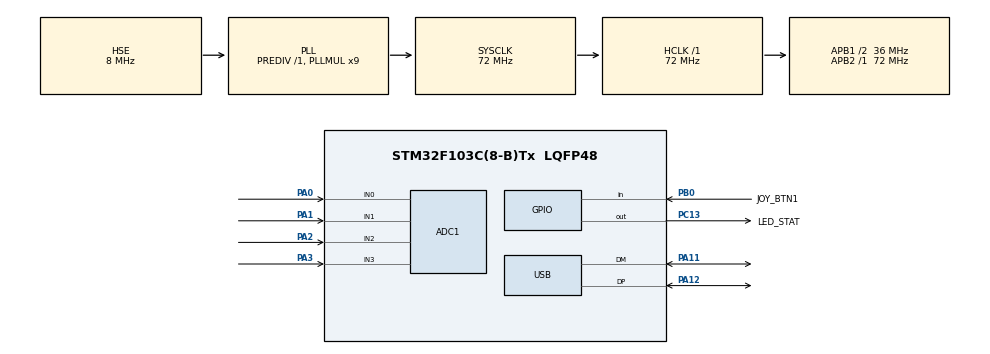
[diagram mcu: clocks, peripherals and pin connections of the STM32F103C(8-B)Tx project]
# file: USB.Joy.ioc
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Mcu.Family=STM32F1
RCC.PLLSourceVirtual=RCC_PLLSOURCE_HSE
NVIC.ADC1_2_IRQn=true\:5\:0\:true\:false\:true\:true\:true
Dma.ADC1.0.Instance=DMA1_Channel1
ADC1.Rank-0\#ChannelRegularConversion=1
PD1-OSC_OUT.Mode=HSE-External-Oscillator
ADC1.ContinuousConvMode=ENABLE
SH.ADCx_IN2.0=ADC1_IN2,IN2
PC13-TAMPER-RTC.Signal=GPIO_Output
RCC.USBPrescaler=RCC_USBCLKSOURCE_PLL_DIV1_5
PA11.Mode=Device
PB0.GPIO_Label=JOY_BTN1
PD0-OSC_IN.Signal=RCC_OSC_IN
RCC.APB1CLKDivider=RCC_HCLK_DIV2
ADC1.SamplingTime-2\#ChannelRegularConversion=ADC_SAMPLETIME_239CYCLES_5
RCC.SYSCLKSource=RCC_SYSCLKSOURCE_PLLCLK
ProjectManager.StackSize=0x400
PA0-WKUP.Signal=ADCx_IN0
PD1-OSC_OUT.Signal=RCC_OSC_OUT
RCC.ADCPresc=RCC_ADCPCLK2_DIV6
PA13.Signal=SYS_JTMS-SWDIO
Dma.ADC1.0.PeriphDataAlignment=DMA_PDATAALIGN_HALFWORD
PA12.Signal=USB_DP
NVIC.USB_HP_CAN1_TX_IRQn=true\:5\:0\:true\:false\:true\:true\:true
ProjectManager.TargetToolchain=STM32CubeIDE
Dma.ADC1.0.Mode=DMA_CIRCULAR
ADC1.Channel-3\#ChannelRegularConversion=ADC_CHANNEL_3
RCC.HCLKFreq_Value=72000000
SH.ADCx_IN3.0=ADC1_IN3,IN3
Dma.ADC1.0.Priority=DMA_PRIORITY_LOW
RCC.APB2TimFreq_Value=72000000
ADC1.Channel-1\#ChannelRegularConversion=ADC_CHANNEL_1
Dma.ADC1.0.Direction=DMA_PERIPH_TO_MEMORY
ADC1.Channel-2\#ChannelRegularConversion=ADC_CHANNEL_2
RCC.USBFreq_Value=48000000
Dma.ADC1.0.MemDataAlignment=DMA_MDATAALIGN_HALFWORD
PA1.Signal=ADCx_IN1
RCC.AHBFreq_Value=72000000
PD0-OSC_IN.Mode=HSE-External-Oscillator
ADC1.Channel-0\#ChannelRegularConversion=ADC_CHANNEL_0
board=custom
PC13-TAMPER-RTC.GPIO_Label=LED_STAT
RCC.PLLMUL=RCC_PLL_MUL9
RCC.APB2Freq_Value=72000000
ADC1.Rank-2\#ChannelRegularConversion=3
PA14.Mode=Serial_Wire
Dma.ADC1.0.PeriphInc=DMA_PINC_DISABLE
NVIC.USB_LP_CAN1_RX0_IRQn=true\:5\:0\:true\:false\:true\:true\:true
SH.ADCx_IN0.0=ADC1_IN0,IN0
ADC1.NbrOfConversion=4
PA13.Mode=Serial_Wire
Mcu.Name=STM32F103C(8-B)Tx
ADC1.SamplingTime-0\#ChannelRegularConversion=ADC_SAMPLETIME_239CYCLES_5
PA2.Signal=ADCx_IN2
ADC1.SamplingTime-1\#ChannelRegularConversion=ADC_SAMPLETIME_239CYCLES_5
RCC.SYSCLKFreq_VALUE=72000000
Mcu.Package=LQFP48
ADC1.master=1
PA12.Mode=Device
ADC1.Rank-3\#ChannelRegularConversion=4
ADC1.SamplingTime-3\#ChannelRegularConversion=ADC_SAMPLETIME_239CYCLES_5
ADC1.Rank-1\#ChannelRegularConversion=2
PA11.Signal=USB_DM
PA14.Signal=SYS_JTCK-SWCLK
Dma.ADC1.0.MemInc=DMA_MINC_ENABLE
ProjectManager.HeapSize=0x200
NVIC.PriorityGroup=NVIC_PRIORITYGROUP_4
ADC1.NbrOfConversionFlag=1
SH.ADCx_IN1.0=ADC1_IN1,IN1
RCC.APB1TimFreq_Value=72000000
NVIC.DMA1_Channel1_IRQn=true\:5\:0\:true\:false\:true\:false\:true
Dma.Request0=ADC1
RCC.APB1Freq_Value=36000000
PB0.Signal=GPIO_Input
PB0.GPIO_PuPd=GPIO_PULLUP
PA3.Signal=ADCx_IN3

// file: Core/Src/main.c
/* USER CODE BEGIN Header */
/**
  ******************************************************************************
  * @file           : main.c
  * @brief          : Main program body
  ******************************************************************************
  * @attention
  *
  * <h2><center>&copy; Copyright (c) 2021 STMicroelectronics.
  * All rights reserved.</center></h2>
  *
  * This software component is licensed by ST under BSD 3-Clause license,
  * the "License"; You may not use this file except in compliance with the
  * License. You may obtain a copy of the License at:
  *                        opensource.org/licenses/BSD-3-Clause
  *
  ******************************************************************************
  */
/* USER CODE END Header */
#include "main.h"
#include "adc.h"
#include "dma.h"
#include "gpio.h"

/* USER CODE BEGIN Includes */
#include "app.h"
/* USER CODE END Includes */

/* USER CODE BEGIN PV */
uint32_t	tick;
/* USER CODE END PV */

void SystemClock_Config(void);

int main(void)
{

  /* MCU Configuration--------------------------------------------------------*/

  /* Reset of all peripherals, Initializes the Flash interface and the Systick. */
  HAL_Init();

  /* Configure the system clock */
  SystemClock_Config();

  /* Initialize all configured peripherals */
  MX_GPIO_Init();
  MX_DMA_Init();
  MX_ADC1_Init();
  /* USER CODE BEGIN 2 */
  appInit();
  /* USER CODE END 2 */

  /* Infinite loop */
  /* USER CODE BEGIN WHILE */
  while (1)
  {
	  tick = HAL_GetTick();
	  ledTask(tick);
	  appTask(tick);
    /* USER CODE END WHILE */

  }
}

void SystemClock_Config(void)
{
  RCC_OscInitTypeDef RCC_OscInitStruct = {0};
  RCC_ClkInitTypeDef RCC_ClkInitStruct = {0};
  RCC_PeriphCLKInitTypeDef PeriphClkInit = {0};

  /** Initializes the RCC Oscillators according to the specified parameters
  * in the RCC_OscInitTypeDef structure.
  */
  RCC_OscInitStruct.OscillatorType = RCC_OSCILLATORTYPE_HSE;
  RCC_OscInitStruct.HSEState = RCC_HSE_ON;
  RCC_OscInitStruct.HSEPredivValue = RCC_HSE_PREDIV_DIV1;
  RCC_OscInitStruct.HSIState = RCC_HSI_ON;
  RCC_OscInitStruct.PLL.PLLState = RCC_PLL_ON;
  RCC_OscInitStruct.PLL.PLLSource = RCC_PLLSOURCE_HSE;
  RCC_OscInitStruct.PLL.PLLMUL = RCC_PLL_MUL9;
  if (HAL_RCC_OscConfig(&RCC_OscInitStruct) != HAL_OK)
  {
    Error_Handler();
  }
  /** Initializes the CPU, AHB and APB buses clocks
  */
  RCC_ClkInitStruct.ClockType = RCC_CLOCKTYPE_HCLK|RCC_CLOCKTYPE_SYSCLK
                              |RCC_CLOCKTYPE_PCLK1|RCC_CLOCKTYPE_PCLK2;
  RCC_ClkInitStruct.SYSCLKSource = RCC_SYSCLKSOURCE_PLLCLK;
  RCC_ClkInitStruct.AHBCLKDivider = RCC_SYSCLK_DIV1;
  RCC_ClkInitStruct.APB1CLKDivider = RCC_HCLK_DIV2;
  RCC_ClkInitStruct.APB2CLKDivider = RCC_HCLK_DIV1;

  if (HAL_RCC_ClockConfig(&RCC_ClkInitStruct, FLASH_LATENCY_2) != HAL_OK)
  {
    Error_Handler();
  }
  PeriphClkInit.PeriphClockSelection = RCC_PERIPHCLK_ADC|RCC_PERIPHCLK_USB;
  PeriphClkInit.AdcClockSelection = RCC_ADCPCLK2_DIV6;
  PeriphClkInit.UsbClockSelection = RCC_USBCLKSOURCE_PLL_DIV1_5;
  if (HAL_RCCEx_PeriphCLKConfig(&PeriphClkInit) != HAL_OK)
  {
    Error_Handler();
  }
}

void Error_Handler(void)
{
  __disable_irq();
  while (1)
  {
  }
}

/************************ (C) COPYRIGHT STMicroelectronics *****END OF FILE****/
